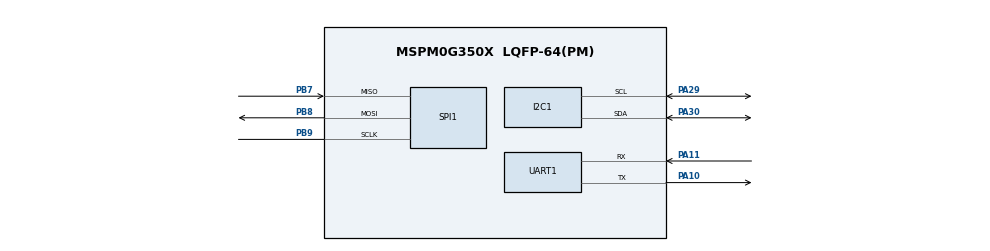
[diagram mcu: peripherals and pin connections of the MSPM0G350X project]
/**
 * @cliArgs --device "MSPM0G350X" --part "Default" --package "LQFP-64(PM)" --product "mspm0_sdk@2.10.00.04"
 * @versions {"tool":"1.26.2+4477"}
 */

/**
 * Import the modules used in this configuration.
 */
const GPIO   = scripting.addModule("/ti/driverlib/GPIO", {}, false);
const GPIO1  = GPIO.addInstance();
const GPIO2  = GPIO.addInstance();
const GPIO3  = GPIO.addInstance();
const I2C    = scripting.addModule("/ti/driverlib/I2C", {}, false);
const I2C1   = I2C.addInstance();
const SPI    = scripting.addModule("/ti/driverlib/SPI", {}, false);
const SPI1   = SPI.addInstance();
const SYSCTL = scripting.addModule("/ti/driverlib/SYSCTL");
const UART   = scripting.addModule("/ti/driverlib/UART", {}, false);
const UART1  = UART.addInstance();

/**
 * Write custom configuration values to the imported modules.
 */
GPIO1.$name                         = "GPIO_VL53L1x";
GPIO1.associatedPins.create(2);
GPIO1.associatedPins[0].$name       = "SHUT";
GPIO1.associatedPins[1].direction   = "INPUT";
GPIO1.associatedPins[1].$name       = "INT";
GPIO1.associatedPins[1].polarity    = "FALL";

const Board = scripting.addModule("/ti/driverlib/Board", {}, false);

GPIO2.$name                              = "CS";
GPIO2.associatedPins[0].$name            = "PIN_0";
GPIO2.associatedPins[0].assignedPort     = "PORTB";
GPIO2.associatedPins[0].assignedPin      = "6";
GPIO2.associatedPins[0].initialValue     = "SET";
GPIO2.associatedPins[0].internalResistor = "PULL_UP";

GPIO3.$name                          = "INT1";
GPIO3.associatedPins[0].$name        = "PIN_1";
GPIO3.associatedPins[0].direction    = "INPUT";
GPIO3.associatedPins[0].assignedPort = "PORTB";
GPIO3.associatedPins[0].assignedPin  = "15";

I2C1.$name                             = "I2C_VL53L1x";
I2C1.basicEnableController             = true;
I2C1.basicControllerStandardBusSpeed   = "Fast";
I2C1.peripheral.$assign                = "I2C1";
I2C1.peripheral.sdaPin.$assign         = "PA30";
I2C1.peripheral.sclPin.$assign         = "PA29";
I2C1.sdaPinConfig.$name                = "ti_driverlib_gpio_GPIOPinGeneric0";
I2C1.sdaPinConfig.hideOutputInversion  = scripting.forceWrite(false);
I2C1.sdaPinConfig.onlyInternalResistor = scripting.forceWrite(false);
I2C1.sdaPinConfig.passedPeripheralType = scripting.forceWrite("Digital");
I2C1.sclPinConfig.$name                = "ti_driverlib_gpio_GPIOPinGeneric1";
I2C1.sclPinConfig.hideOutputInversion  = scripting.forceWrite(false);
I2C1.sclPinConfig.onlyInternalResistor = scripting.forceWrite(false);
I2C1.sclPinConfig.passedPeripheralType = scripting.forceWrite("Digital");

SPI1.$name                      = "SPI_0";
SPI1.targetBitRate              = 16000000;
SPI1.frameFormat                = "MOTO3";
SPI1.sclkPinConfig.$name        = "ti_driverlib_gpio_GPIOPinGeneric4";
SPI1.mosiPinConfig.$name        = "ti_driverlib_gpio_GPIOPinGeneric5";
SPI1.misoPinConfig.$name        = "ti_driverlib_gpio_GPIOPinGeneric6";
SPI1.peripheral.$assign         = "SPI1";
SPI1.peripheral.sclkPin.$assign = "PB9";
SPI1.peripheral.mosiPin.$assign = "PB8";
SPI1.peripheral.misoPin.$assign = "PB7";

SYSCTL.forceDefaultClkConfig = true;

UART1.$name                    = "UART_0";
UART1.targetBaudRate           = 115200;
UART1.peripheral.$assign       = "UART0";
UART1.peripheral.rxPin.$assign = "PA11";
UART1.peripheral.txPin.$assign = "PA10";
UART1.txPinConfig.$name        = "ti_driverlib_gpio_GPIOPinGeneric2";
UART1.rxPinConfig.$name        = "ti_driverlib_gpio_GPIOPinGeneric3";

/**
 * Pinmux solution for unlocked pins/peripherals. This ensures that minor changes to the automatic solver in a future
 * version of the tool will not impact the pinmux you originally saw.  These lines can be completely deleted in order to
 * re-solve from scratch.
 */
GPIO1.associatedPins[0].pin.$suggestSolution = "PB13";
GPIO1.associatedPins[1].pin.$suggestSolution = "PB14";
Board.peripheral.$suggestSolution            = "DEBUGSS";
Board.peripheral.swclkPin.$suggestSolution   = "PA20";
Board.peripheral.swdioPin.$suggestSolution   = "PA19";
GPIO2.associatedPins[0].pin.$suggestSolution = "PB6";
GPIO3.associatedPins[0].pin.$suggestSolution = "PB15";
SYSCTL.peripheral.$suggestSolution           = "SYSCTL";
